AUTOSAR XML (schema 00049)
package /DataType/Implementation/CPP
  5 x std cpp implementation data type:
    CameraFrameStructure: category=STRUCTURE
      namespaces:
        symbol props ara
        symbol props sensor
      4 x cpp implementation data type element:
        height: type-reference=uint16_t
        width: type-reference=uint16_t
        encoding: type-reference=EncodingType
        vector: type-reference=SensorVectorType
    EncodingType: category=STRING
      namespaces:
        symbol props cv
        symbol props sensor
    ImencodeExtString: category=STRING
      namespaces:
        symbol props cv
        symbol props imencode
    SensorImencodeType: category=STRUCTURE
      namespaces:
        symbol props sensor
        symbol props imencode
      cpp implementation data type element extension: is-optional=false, type-reference=ImencodeExtString
      cpp implementation data type element inputArray: type-reference=uint8_t
      cpp implementation data type element buffer: type-reference=uint8_t
    SensorVectorType: category=VECTOR, cpp-template-argument{inplace=false, template-type=uint8_t}
      namespaces:
        symbol props ara
        symbol props sensor
package /DataType/Implementation/CPP/Allocator
  allocator imemcode
    namespaces:
      symbol props cv
      symbol props imemcode
package /PortInterface/Service
  service interface transferData
    namespaces:
      symbol props sensor
      symbol props transfer
    events:
      data Event_transferData: type=SensorVectorType
  service interface transferData_v2
    namespaces:
      symbol props sensor
      symbol props transv2
    events:
      data Event_RequestData: type=SensorVectorType
    methods:
      operation RequestData: fire-and-forget=false
        arg isRequest: type=bool, direction=IN
        arg outputVector: type=SensorVectorType, direction=OUT
package /System/Communication/TpConfig
  someip tp config SomeIPTPCfg: communication-cluster=EthernetCluster
package /System/Service/Deployment
  someip service interface deployment transferData: service-interface=transferData, service-interface-id=21, service-interface-version={major-version=1, minor-version=0}
    someip event deployment Event_transferData: event=Event_transferData, event-id=1, transport-protocol=UDP
    someip event group Eventgroup_Event_transferData: event-group-id=10, event=Event_transferData
  someip service interface deployment transferData_v2: service-interface=transferData_v2, service-interface-id=22, service-interface-version={major-version=1, minor-version=0}
    someip event deployment Event_RequestData: event=Event_RequestData, event-id=1, maximum-segment-length=1392, serializer=SOMEIP, transport-protocol=UDP
    someip method deployment RequestData: method=RequestData, maximum-segment-length-request=1392, maximum-segment-length-response=1392, method-id=1, transport-protocol=UDP
    someip event group Eventgroup_Event_RequestData: event-group-id=21, event=Event_RequestData
package /System/Service/Endpoint
  4 x someip service instance to machine mapping, all with communication-connector=eth0:
    TransferData_ConsumerEndpoint: service-instance=Consumer_transferData, tcp-port=35101, udp-port=35101
    TransferData_ProviderEndpoint: service-instance=Provider_transferData, tcp-port=35001, udp-port=35001
    transferData_v2_ConsumerEndpoint: service-instance=Consumer_transferData_v2, tcp-port=35102, udp-port=35102
    transferData_v2_ProviderEndpoint: service-instance=Provider_transferData_v2, tcp-port=35002, udp-port=35002
package /System/Service/Instance
  required someip service instance Consumer_transferData: service-interface-deployment=transferData, required-minor-version=ANY, required-service-instance-id=ANY, sd-client-config=Consumer_transferDataSdClientConfig, version-driven-find-behavior=EXACT-OR-ANY-MINOR-VERSION
    someip required event group Eventgroup_Event_transferData: event-group=Eventgroup_Event_transferData, sd-client-event-group-timing-config=Eventgroup_Event_transferDataSdEventgroupConfig
  required someip service instance Consumer_transferData_v2: service-interface-deployment=transferData_v2, required-minor-version=ANY, required-service-instance-id=ANY, sd-client-config=Consumer_transferData_v2SdClientConfig, version-driven-find-behavior=EXACT-OR-ANY-MINOR-VERSION
    someip required event group Eventgroup_Event_RequestData: event-group=Eventgroup_Event_RequestData, sd-client-event-group-timing-config=Eventgroup_Event_RequestDataSdEventgroupConfig
  provided someip service instance Provider_transferData: service-interface-deployment=transferData, sd-server-config=Provider_transferDataSdServerConfig, service-instance-id=1
    someip provided event group Eventgroup_Event_transferData: event-group=Eventgroup_Event_transferData, multicast-threshold=0
  provided someip service instance Provider_transferData_v2: service-interface-deployment=transferData_v2, sd-server-config=Provider_transferData_v2SdServerConfig, service-instance-id=2
    someip provided event group Eventgroup_Event_RequestData: event-group=Eventgroup_Event_RequestData, multicast-threshold=0
package /System/Service/TimingConfig
  someip sd server service instance config Cli_transferDataSdServerConfig: initial-offer-behavior={initial-delay-max-value=0.1, initial-delay-min-value=0.01, initial-repetitions-base-delay=0.2, initial-repetitions-max=3}, offer-cyclic-delay=1.0, request-response-delay={max-value=0.0, min-value=0.0}, service-offer-time-to-live=16777215
  someip sd client service instance config Consumer_transferDataSdClientConfig: initial-find-behavior={initial-delay-max-value=0.1, initial-delay-min-value=0.01, initial-repetitions-base-delay=0.2, initial-repetitions-max=3}, service-find-time-to-live=16777215
  someip sd client service instance config Consumer_transferData_v2SdClientConfig: initial-find-behavior={initial-delay-max-value=0.1, initial-delay-min-value=0.01, initial-repetitions-base-delay=0.2, initial-repetitions-max=3}, service-find-time-to-live=16777215
  someip sd client event group timing config Eventgroup_Event_RequestDataSdEventgroupConfig: request-response-delay={max-value=0.0, min-value=0.0}, time-to-live=16777215
  someip sd client event group timing config Eventgroup_Event_transferDataSdEventgroupConfig: request-response-delay={max-value=0.0, min-value=0.0}, time-to-live=16777215
  someip sd server service instance config Provider_transferDataSdServerConfig: initial-offer-behavior={initial-delay-max-value=0.1, initial-delay-min-value=0.01, initial-repetitions-base-delay=0.2, initial-repetitions-max=3}, offer-cyclic-delay=1.0, request-response-delay={max-value=0.0, min-value=0.0}, service-offer-time-to-live=16777215
  someip sd server service instance config Provider_transferData_v2SdServerConfig: initial-offer-behavior={initial-delay-max-value=0.1, initial-delay-min-value=0.01, initial-repetitions-base-delay=0.2, initial-repetitions-max=3}, offer-cyclic-delay=1.0, request-response-delay={max-value=0.0, min-value=0.0}, service-offer-time-to-live=16777215
package /SwComponent/AdaptiveApplication
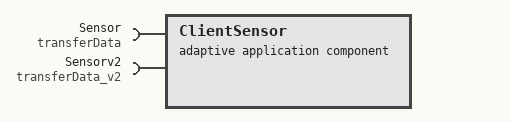
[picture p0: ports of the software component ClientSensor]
  adaptive application sw component type ClientSensor
    require port Sensor: required-interface=transferData
    require port Sensorv2: required-interface=transferData_v2
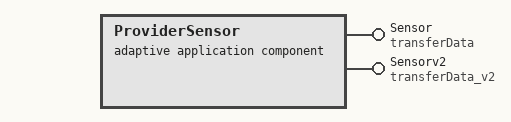
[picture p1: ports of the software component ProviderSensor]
  adaptive application sw component type ProviderSensor
    provide port Sensor: provided-interface=transferData
    provide port Sensorv2: provided-interface=transferData_v2
package /AdaptiveApplication/DltConfig
  dlt log channel to process mapping DltLogChannelToProcessMapping_ClientSensor_TO_ClientSensor: dlt-log-channel=ClientSensor, process=ClientSensor
  dlt log channel to process mapping DltLogChannelToProcessMapping_ProviderSensor_TO_ProviderSensor: dlt-log-channel=ProviderSensor, process=ProviderSensor
package /AdaptiveApplication/Executable
  executable ClientSensor: category=APPLICATION_LEVEL, logging-behavior=USES-LOGGING, reporting-behavior=REPORTS-EXECUTION-STATE, version=1.0.0
    root sw component prototype RootSwComponent: application-type=ClientSensor
  executable ProviderSensor: category=APPLICATION_LEVEL, logging-behavior=USES-LOGGING, reporting-behavior=REPORTS-EXECUTION-STATE, version=1.0.0
    root sw component prototype RootSwComponent: application-type=ProviderSensor
package /AdaptiveApplication/Manifest
  4 x service instance to port prototype mapping:
    ClientSensor_RootSwComponent_Sensor: port-prototype=RootSwComponent.Sensor, service-instance=Consumer_transferData
    ClientSensor_RootSwComponent_Sensorv2: port-prototype=RootSwComponent.Sensorv2, service-instance=Consumer_transferData_v2
    ProviderSensor_RootSwComponent_Sensor: port-prototype=RootSwComponent.Sensor, service-instance=Provider_transferData
    ProviderSensor_RootSwComponent_Sensorv2: port-prototype=RootSwComponent.Sensorv2, service-instance=Provider_transferData_v2
package /AdaptiveApplication/Process
  process ClientSensor: executable=ClientSensor, state-dependent-startup-config{execution-dependency=ProviderSensor.Running, function-group-state=MachineFG.Startup, resource-group=ResourceGroup, startup-config=ClientSensor}
    process state machine ClientSensor: type=ProcessState
  process ProviderSensor: executable=ProviderSensor, state-dependent-startup-config{execution-dependency=CM.Running, function-group-state=MachineFG.Startup, resource-group=ResourceGroup, startup-config=ProviderSensor}
    process state machine ProviderSensor: type=ProcessState
package /Platform/ProcessToMachine
  process to machine mapping set ProcessToHPC_MachineMapping
    process to machine mapping ClientSensor_To_HPC_Machine_Mapping: machine=HPC_Machine, process=ClientSensor
    process to machine mapping ProviderSensor_To_HPC_Machine_Mapping: machine=HPC_Machine, process=ProviderSensor
